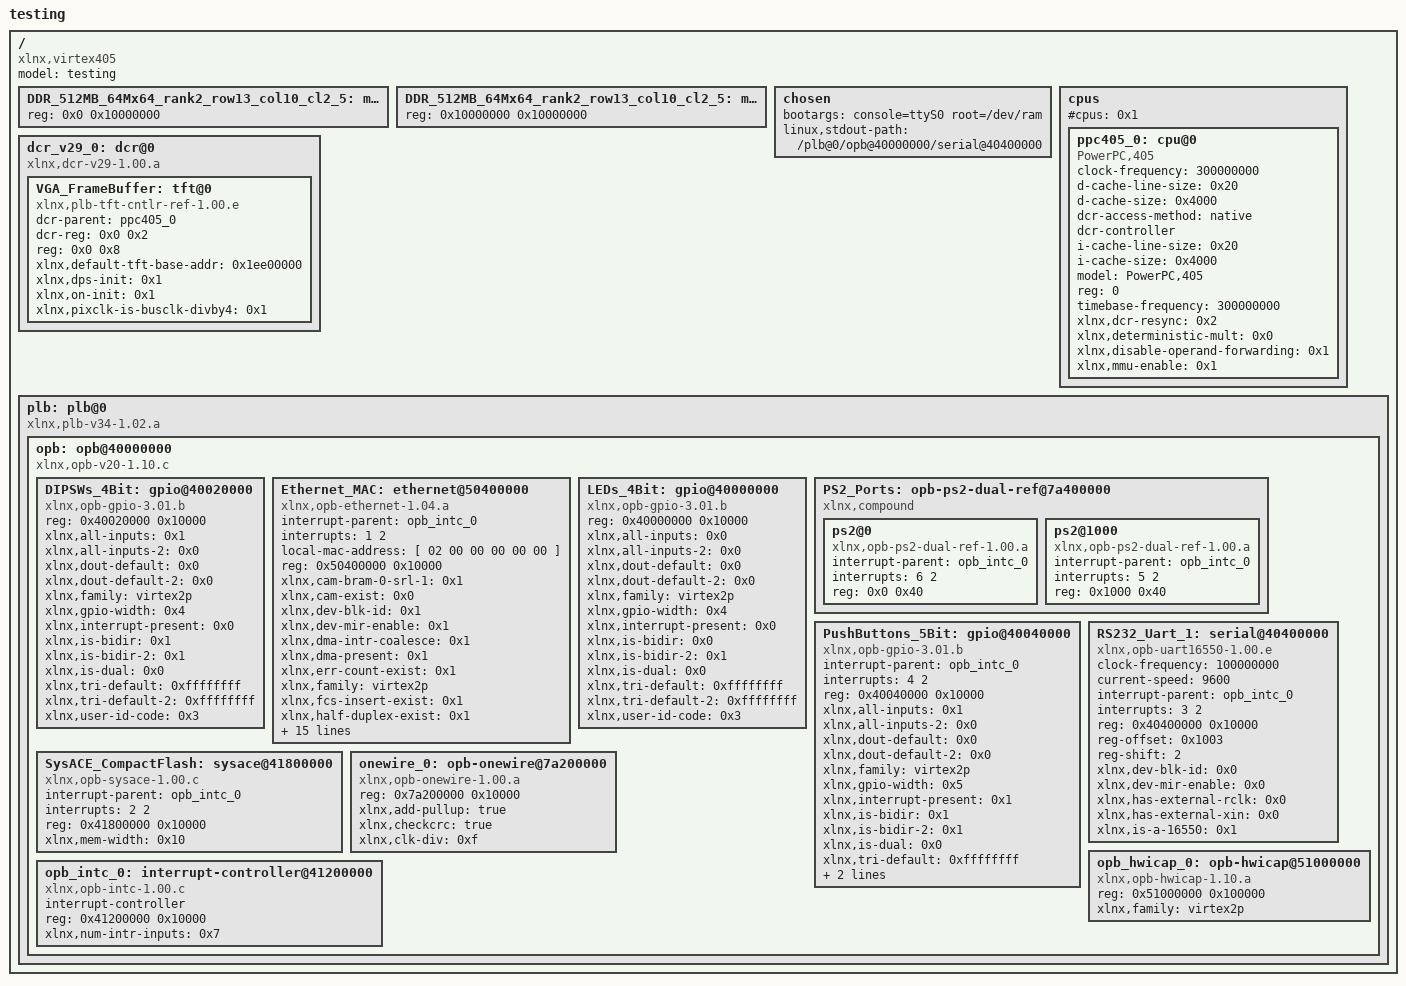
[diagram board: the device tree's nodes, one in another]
/*
 * Device Tree Generator version: 1.1
 *
 * (C) Copyright 2007-2008 Xilinx, Inc.
 * (C) Copyright 2007-2008 Michal Simek
 *
 * Michal SIMEK <monstr@monstr.eu>
 *
 * This program is free software; you can redistribute it and/or
 * modify it under the terms of the GNU General Public License as
 * published by the Free Software Foundation; either version 2 of
 * the License, or (at your option) any later version.
 *
 * This program is distributed in the hope that it will be useful,
 * but WITHOUT ANY WARRANTY; without even the implied warranty of
 * MERCHANTABILITY or FITNESS FOR A PARTICULAR PURPOSE. See the
 * GNU General Public License for more details.
 *
 * You should have received a copy of the GNU General Public License
 * along with this program; if not, write to the Free Software
 * Foundation, Inc., 59 Temple Place, Suite 330, Boston,
 * MA 02111-1307 USA
 *
 * CAUTION: This file is automatically generated by libgen.
 * Version: Xilinx EDK 9.2.02 EDK_Jm_SP2.3
 *
 * XPS project directory: opb_eth_tft_cf
 */

/dts-v1/;
/ {
	#address-cells = <1>;
	#size-cells = <1>;
	compatible = "xlnx,virtex405", "xlnx,virtex";
	model = "testing";
	DDR_512MB_64Mx64_rank2_row13_col10_cl2_5: memory@0 {
		device_type = "memory";
		reg = < 0x0 0x10000000 >;
	} ;
	DDR_512MB_64Mx64_rank2_row13_col10_cl2_5: memory@10000000 {
		device_type = "memory";
		reg = < 0x10000000 0x10000000 >;
	} ;
	chosen {
		bootargs = "console=ttyS0 root=/dev/ram";
		linux,stdout-path = "/plb@0/opb@40000000/serial@40400000";
	} ;
	cpus {
		#address-cells = <1>;
		#cpus = <0x1>;
		#size-cells = <0>;
		ppc405_0: cpu@0 {
			clock-frequency = <300000000>;
			compatible = "PowerPC,405", "ibm,ppc405";
			d-cache-line-size = <0x20>;
			d-cache-size = <0x4000>;
			dcr-access-method = "native";
			dcr-controller ;
			device_type = "cpu";
			i-cache-line-size = <0x20>;
			i-cache-size = <0x4000>;
			model = "PowerPC,405";
			reg = <0>;
			timebase-frequency = <300000000>;
			xlnx,dcr-resync = <0x2>;
			xlnx,deterministic-mult = <0x0>;
			xlnx,disable-operand-forwarding = <0x1>;
			xlnx,mmu-enable = <0x1>;
		} ;
	} ;
	dcr_v29_0: dcr@0 {
		#address-cells = <1>;
		#size-cells = <1>;
		compatible = "xlnx,dcr-v29-1.00.a", "simple-bus";
		VGA_FrameBuffer: tft@0 {
			compatible = "xlnx,plb-tft-cntlr-ref-1.00.e";
			dcr-parent = <&ppc405_0>;
			dcr-reg = < 0x0 0x2 >;
			reg = < 0x0 0x8 >;
			xlnx,default-tft-base-addr = <0x1ee00000>;
			xlnx,dps-init = <0x1>;
			xlnx,on-init = <0x1>;
			xlnx,pixclk-is-busclk-divby4 = <0x1>;
		} ;
	} ;
	plb: plb@0 {
		#address-cells = <1>;
		#size-cells = <1>;
		compatible = "xlnx,plb-v34-1.02.a", "simple-bus";
		ranges ;
		opb: opb@40000000 {
			#address-cells = <1>;
			#size-cells = <1>;
			compatible = "xlnx,opb-v20-1.10.c", "simple-bus";
			ranges = < 0x40000000 0x40000000 0x40000000 >;
			DIPSWs_4Bit: gpio@40020000 {
				compatible = "xlnx,opb-gpio-3.01.b";
				reg = < 0x40020000 0x10000 >;
				xlnx,all-inputs = <0x1>;
				xlnx,all-inputs-2 = <0x0>;
				xlnx,dout-default = <0x0>;
				xlnx,dout-default-2 = <0x0>;
				xlnx,family = "virtex2p";
				xlnx,gpio-width = <0x4>;
				xlnx,interrupt-present = <0x0>;
				xlnx,is-bidir = <0x1>;
				xlnx,is-bidir-2 = <0x1>;
				xlnx,is-dual = <0x0>;
				xlnx,tri-default = <0xffffffff>;
				xlnx,tri-default-2 = <0xffffffff>;
				xlnx,user-id-code = <0x3>;
			} ;
			Ethernet_MAC: ethernet@50400000 {
				compatible = "xlnx,opb-ethernet-1.04.a";
				device_type = "network";
				interrupt-parent = <&opb_intc_0>;
				interrupts = < 1 2 >;
				local-mac-address = [ 02 00 00 00 00 00 ];
				reg = < 0x50400000 0x10000 >;
				xlnx,cam-bram-0-srl-1 = <0x1>;
				xlnx,cam-exist = <0x0>;
				xlnx,dev-blk-id = <0x1>;
				xlnx,dev-mir-enable = <0x1>;
				xlnx,dma-intr-coalesce = <0x1>;
				xlnx,dma-present = <0x1>;
				xlnx,err-count-exist = <0x1>;
				xlnx,family = "virtex2p";
				xlnx,fcs-insert-exist = <0x1>;
				xlnx,half-duplex-exist = <0x1>;
				xlnx,include-dev-pencoder = <0x1>;
				xlnx,ipif-rdfifo-depth = <0x8000>;
				xlnx,ipif-wrfifo-depth = <0x8000>;
				xlnx,jumbo-exist = <0x0>;
				xlnx,mac-fifo-bram-1-srl-0 = <0x0>;
				xlnx,mac-fifo-depth = <0x40>;
				xlnx,mii-exist = <0x1>;
				xlnx,miim-clkdvd = <0x1f>;
				xlnx,pad-insert-exist = <0x1>;
				xlnx,reset-present = <0x1>;
				xlnx,rx-dre-type = <0x0>;
				xlnx,rx-include-csum = <0x0>;
				xlnx,source-addr-insert-exist = <0x1>;
				xlnx,tx-dre-type = <0x0>;
				xlnx,tx-include-csum = <0x0>;
			} ;
			LEDs_4Bit: gpio@40000000 {
				compatible = "xlnx,opb-gpio-3.01.b";
				reg = < 0x40000000 0x10000 >;
				xlnx,all-inputs = <0x0>;
				xlnx,all-inputs-2 = <0x0>;
				xlnx,dout-default = <0x0>;
				xlnx,dout-default-2 = <0x0>;
				xlnx,family = "virtex2p";
				xlnx,gpio-width = <0x4>;
				xlnx,interrupt-present = <0x0>;
				xlnx,is-bidir = <0x0>;
				xlnx,is-bidir-2 = <0x1>;
				xlnx,is-dual = <0x0>;
				xlnx,tri-default = <0xffffffff>;
				xlnx,tri-default-2 = <0xffffffff>;
				xlnx,user-id-code = <0x3>;
			} ;
			PS2_Ports: opb-ps2-dual-ref@7a400000 {
				#address-cells = <1>;
				#size-cells = <1>;
				compatible = "xlnx,compound";
				ranges = < 0x0 0x7a400000 0x10000 >;
				ps2@0 {
					compatible = "xlnx,opb-ps2-dual-ref-1.00.a";
					interrupt-parent = <&opb_intc_0>;
					interrupts = < 6 2 >;
					reg = < 0x0 0x40 >;
				} ;
				ps2@1000 {
					compatible = "xlnx,opb-ps2-dual-ref-1.00.a";
					interrupt-parent = <&opb_intc_0>;
					interrupts = < 5 2 >;
					reg = < 0x1000 0x40 >;
				} ;
			} ;
			PushButtons_5Bit: gpio@40040000 {
				compatible = "xlnx,opb-gpio-3.01.b";
				interrupt-parent = <&opb_intc_0>;
				interrupts = < 4 2 >;
				reg = < 0x40040000 0x10000 >;
				xlnx,all-inputs = <0x1>;
				xlnx,all-inputs-2 = <0x0>;
				xlnx,dout-default = <0x0>;
				xlnx,dout-default-2 = <0x0>;
				xlnx,family = "virtex2p";
				xlnx,gpio-width = <0x5>;
				xlnx,interrupt-present = <0x1>;
				xlnx,is-bidir = <0x1>;
				xlnx,is-bidir-2 = <0x1>;
				xlnx,is-dual = <0x0>;
				xlnx,tri-default = <0xffffffff>;
				xlnx,tri-default-2 = <0xffffffff>;
				xlnx,user-id-code = <0x3>;
			} ;
			RS232_Uart_1: serial@40400000 {
				clock-frequency = <100000000>;
				compatible = "xlnx,opb-uart16550-1.00.e", "ns16550";
				current-speed = <9600>;
				device_type = "serial";
				interrupt-parent = <&opb_intc_0>;
				interrupts = < 3 2 >;
				reg = < 0x40400000 0x10000 >;
				reg-offset = <0x1003>;
				reg-shift = <2>;
				xlnx,dev-blk-id = <0x0>;
				xlnx,dev-mir-enable = <0x0>;
				xlnx,has-external-rclk = <0x0>;
				xlnx,has-external-xin = <0x0>;
				xlnx,is-a-16550 = <0x1>;
			} ;
			SysACE_CompactFlash: sysace@41800000 {
				compatible = "xlnx,opb-sysace-1.00.c";
				interrupt-parent = <&opb_intc_0>;
				interrupts = < 2 2 >;
				reg = < 0x41800000 0x10000 >;
				xlnx,mem-width = <0x10>;
			} ;
			onewire_0: opb-onewire@7a200000 {
				compatible = "xlnx,opb-onewire-1.00.a";
				reg = < 0x7a200000 0x10000 >;
				xlnx,add-pullup = "true";
				xlnx,checkcrc = "true";
				xlnx,clk-div = <0xf>;
			} ;
			opb_hwicap_0: opb-hwicap@51000000 {
				compatible = "xlnx,opb-hwicap-1.10.a";
				reg = < 0x51000000 0x100000 >;
				xlnx,family = "virtex2p";
			} ;
			opb_intc_0: interrupt-controller@41200000 {
				#interrupt-cells = <0x2>;
				compatible = "xlnx,opb-intc-1.00.c";
				interrupt-controller ;
				reg = < 0x41200000 0x10000 >;
				xlnx,num-intr-inputs = <0x7>;
			} ;
		} ;
	} ;
}  ;
